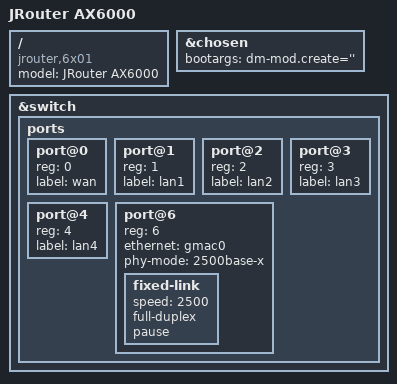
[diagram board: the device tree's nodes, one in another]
// SPDX-License-Identifier: (GPL-2.0 OR MIT)

// For models: 6401, 6601, 6701, 6801
/dts-v1/;
#include "mt7986a-jrouter-common.dtsi"

/ {
    model = "JRouter AX6000";
    compatible = "jrouter,6x01", "mediatek,mt7986a";
};

&chosen {
    bootargs = "dm-mod.create=''";
};

&switch {
    ports {
        #address-cells = <1>;
        #size-cells = <0>;

        port@0 {
            reg = <0>;
            label = "wan";
        };

        port@1 {
            reg = <1>;
            label = "lan1";
        };

        port@2 {
            reg = <2>;
            label = "lan2";
        };

        port@3 {
            reg = <3>;
            label = "lan3";
        };

        port@4 {
            reg = <4>;
            label = "lan4";
        };

        port@6 {
            reg = <6>;
            ethernet = <&gmac0>;
            phy-mode = "2500base-x";

            fixed-link {
                speed = <2500>;
                full-duplex;
                pause;
            };
        };
    };
};


